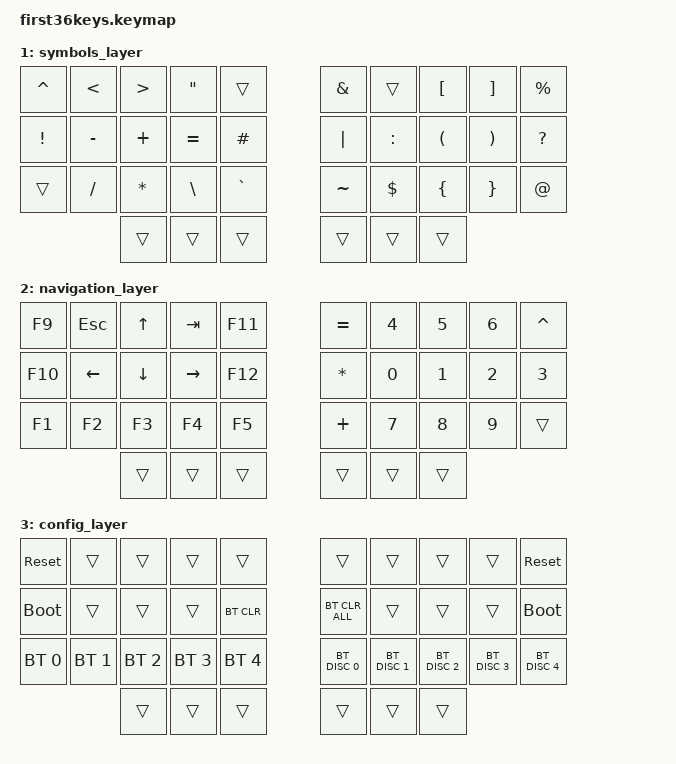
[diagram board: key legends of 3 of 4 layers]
#include <behaviors.dtsi>
#include <dt-bindings/zmk/keys.h>
#include <dt-bindings/zmk/bt.h>

// Home row mods macro
#define HRML(k1,k2,k3,k4) &ht_LEFT_PINKY LGUI k1  &ht_LEFT_RING LALT k2  &ht_LEFT_MIDDLE LCTRL k3  &ht_LEFT_INDEX LSHFT k4
#define HRMR(k1,k2,k3,k4) &ht_RIGHT_PINKY RSHFT k1  &ht_RIGHT_RING RCTRL k2  &ht_RIGHT_MIDDLE RALT k3  &ht_RIGHT_INDEX RGUI k4
#define LEFT_PINKY_HOLDING_TIME 250
#define LEFT_RING_HOLDING_TIME 200
#define LEFT_MIDDLE_HOLDING_TIME 200
#define LEFT_INDEX_HOLDING_TIME 200
#define RIGHT_PINKY_HOLDING_TIME 250
#define RIGHT_RING_HOLDING_TIME 200
#define RIGHT_MIDDLE_HOLDING_TIME 200
#define RIGHT_INDEX_HOLDING_TIME 200

/ {

    keymap {
        compatible = "zmk,keymap";
        default_layer {
            bindings = <
/*        ╭──────────┬──────────┬──────────┬──────────┬──────────╮   ╭──────────┬──────────┬──────────┬──────────┬──────────╮*/
/*        │  J       │  C       │  Y       │  F       │  K       │   │  Z       │  L       │  , <     │  U       │  Q       │*/
            &kp J      &kp C      &kp Y      &kp F      &kp K          &kp Z      &kp L      &kp COMMA  &kp U      &kp Q
/*        ├──────────┼──────────┼──────────┼──────────┼──────────┤   ├──────────┼──────────┼──────────┼──────────┼──────────┤*/
/*        │  R       │  S       │  T       │  H       │  D       │   │  M       │  N       │  A       │  I       │  O       │*/
            HRML(R,        S,         T,         H)     &kp D          &kp M      HRMR(N,        A,         I,        O)
/*        ├──────────┼──────────┼──────────┼──────────┼──────────┤   ├──────────┼──────────┼──────────┼──────────┼──────────┤*/
/*        │  '       │  V       │  G       │  P       │  B       │   │  X       │  W       │          │ ; :      │ . <      │*/
            &kp APOS   &kp V      &kp G      &kp P      &kp B          &kp X      &kp W      &kp ENTER  &kp SEMI   &kp DOT 
/*        ╰──────────┴──────────┴──────────┼──────────┼──────────┤   ├──────────┼──────────┼──────────┴──────────┴──────────╯*/
                                  &kp E      &sl 1      &sl 2          &sk RSHFT &shift_backspace   &kp SPACE
/*                              ╰──────────┴──────────┴──────────╯   ╰──────────┴──────────┴──────────╯*/
            >;
        };

        symbols_layer {
            bindings = <
/*        ╭──────────┬──────────┬──────────┬──────────┬──────────╮   ╭──────────┬──────────┬──────────┬──────────┬──────────╮*/
/*        │ ^        │  <       │  >       │  DQT     │          │   │  &       │          │  [       │  ]       │  %       │*/
            &kp CARET   &kp LT     &kp GT     &kp DQT    &trans         &kp AMPS   &trans     &kp LBKT   &kp RBKT   &kp PRCNT
/*        ├──────────┼──────────┼──────────┼──────────┼──────────┤   ├──────────┼──────────┼──────────┼──────────┼──────────┤*/
/*        │ !        │  -       │  +       │  =       │  #       │   │  |       │  :       │  (       │  )       │  ?       │*/
            &kp EXCL   &kp MINUS  &kp PLUS   &kp EQUAL  &kp HASH       &kp PIPE   &kp COLON  &kp LPAR   &kp RPAR   &kp QMARK
/*        ├──────────┼──────────┼──────────┼──────────┼──────────┤   ├──────────┼──────────┼──────────┼──────────┼──────────┤*/
/*        │          │  /       │  *       │  \       │  `       │   │  ~       │  $       │  {       │  }       │  @       │*/
            &trans     &kp FSLH   &kp STAR   &kp BSLH   &kp GRAVE      &kp TILDE  &kp DLLR   &kp LBRC   &kp RBRC   &kp AT
/*        ╰──────────┴──────────┴──────────┼──────────┼──────────┤   ├──────────┼──────────┼──────────┴──────────┴──────────╯*/
                                  &trans     &trans     &trans         &trans     &trans     &trans
/*                              ╰──────────┴──────────┴──────────╯   ╰──────────┴──────────┴──────────╯*/
            >;
        };

        navigation_layer {
            bindings = <
/*        ╭──────────┬──────────┬──────────┬──────────┬──────────╮   ╭──────────┬──────────┬──────────┬──────────┬──────────╮*/
/*        │          │  ESC     │  UP      │  TAB     │          │   │  =       │  4       │  5       │  6       │  ^       │*/
            &kp F9     &kp ESC    &kp UP     &kp TAB    &kp F11        &kp EQUAL  &kp N4     &kp N5     &kp N6     &kp CARET
/*        ├──────────┼──────────┼──────────┼──────────┼──────────┤   ├──────────┼──────────┼──────────┼──────────┼──────────┤*/
/*        │          │  LEFT    │  DOWN    │  RIGHT   │          │   │  *       │  0       │  1       │  2       │  3       │*/
            &kp F10     &kp LEFT   &kp DOWN   &kp RIGHT &kp F12         &kp STAR   &kp N0     &kp N1     &kp N2     &kp N3
/*        ├──────────┼──────────┼──────────┼──────────┼──────────┤   ├──────────┼──────────┼──────────┼──────────┼──────────┤*/
/*        │  F1      │  F2      │  F3      │  F4      │  F5      │   │  +       │  7       │  8       │  9       │  .       │*/
            &kp F1     &kp F2     &kp F3     &kp F4     &kp F5         &kp PLUS   &kp N7     &kp N8     &kp N9     &trans
/*        ╰──────────┴──────────┴──────────┼──────────┼──────────┤   ├──────────┼──────────┼──────────┴──────────┴──────────╯*/
                                  &trans     &trans     &trans         &trans     &trans     &trans
/*                              ╰──────────┴──────────┴──────────╯   ╰──────────┴──────────┴──────────╯*/
            >;
        };

        config_layer {
            bindings = <
/*        ╭──────────┬──────────┬──────────┬──────────┬──────────╮   ╭──────────┬──────────┬──────────┬──────────┬──────────╮*/
/*        │ RESET    │          │          │          │          │   │          │          │          │          │  RESET   │*/
           &sys_reset  &trans     &trans     &trans    &trans          &trans     &trans     &trans     &trans    &sys_reset
/*        ├──────────┼──────────┼──────────┼──────────┼──────────┤   ├──────────┼──────────┼──────────┼──────────┼──────────┤*/
/*        │BOOTLOADER│          │          │          │BT CLEAR  │   │          │          │          │          │BOOTLOADER│*/
          &bootloader  &trans     &trans     &trans    &bt BT_CLR     &bt BT_CLR_ALL &trans  &trans     &trans    &bootloader
/*        ├──────────┼──────────┼──────────┼──────────┼──────────┤   ├──────────┼──────────┼──────────┼──────────┼──────────┤*/
/*        │PROFILE 0 │PROFILE 1 │PROFILE 2 │PROFILE 3 │PROFILE 4 │   │          │          │          │          │          │*/
 &bt BT_SEL 0 &bt BT_SEL 1 &bt BT_SEL 2 &bt BT_SEL 3 &bt BT_SEL 4     &bt BT_DISC 0 &bt BT_DISC 1 &bt BT_DISC 2 &bt BT_DISC 3 &bt BT_DISC 4
/*        ╰──────────┴──────────┴──────────┼──────────┼──────────┤   ├──────────┼──────────┼──────────┴──────────┴──────────╯*/
                                  &trans     &trans     &trans         &trans     &trans     &trans
/*                              ╰──────────┴──────────┴──────────╯   ╰──────────┴──────────┴──────────╯*/
            >;
        };
    };
    conditional_layers {
        compatible = "zmk,conditional-layers";
        config_layer {
            if-layers = <1 2>;
            then-layer = <3>;
        };
    };
    
    behaviors {
        ht_LEFT_PINKY: hold_tap {
            compatible = "zmk,behavior-hold-tap";
            #binding-cells = <2>;
            flavor = "tap-preferred";
            tapping-term-ms = <LEFT_PINKY_HOLDING_TIME>;
            quick-tap-ms = <300>;
            require-prior-idle-ms = <250>;
            bindings = <&kp>, <&kp>;
        };
    };

    behaviors {
        ht_LEFT_RING: hold_tap {
            compatible = "zmk,behavior-hold-tap";
            #binding-cells = <2>;
            flavor = "tap-preferred";
            tapping-term-ms = <LEFT_RING_HOLDING_TIME>;
            quick-tap-ms = <300>;
            require-prior-idle-ms = <250>;
            bindings = <&kp>, <&kp>;
        };
    };
    
    behaviors {
        ht_LEFT_MIDDLE: hold_tap {
            compatible = "zmk,behavior-hold-tap";
            #binding-cells = <2>;
            flavor = "tap-preferred";
            tapping-term-ms = <LEFT_MIDDLE_HOLDING_TIME>;
            quick-tap-ms = <300>;
            require-prior-idle-ms = <250>;
            bindings = <&kp>, <&kp>;
        };
    };

    behaviors {
        ht_LEFT_INDEX: hold_tap {
            compatible = "zmk,behavior-hold-tap";
            #binding-cells = <2>;
            flavor = "tap-preferred";
            tapping-term-ms = <LEFT_INDEX_HOLDING_TIME>;
            quick-tap-ms = <300>;
            require-prior-idle-ms = <150>;
            bindings = <&kp>, <&kp>;
        };
    };
    
    behaviors {
        ht_RIGHT_PINKY: hold_tap {
            compatible = "zmk,behavior-hold-tap";
            #binding-cells = <2>;
            flavor = "tap-preferred";
            tapping-term-ms = <RIGHT_PINKY_HOLDING_TIME>;
            quick-tap-ms = <300>;
            require-prior-idle-ms = <250>;
            bindings = <&kp>, <&kp>;
        };
    };

    behaviors {
        ht_RIGHT_RING: hold_tap {
            compatible = "zmk,behavior-hold-tap";
            #binding-cells = <2>;
            flavor = "tap-preferred";
            tapping-term-ms = <RIGHT_RING_HOLDING_TIME>;
            quick-tap-ms = <300>;
            require-prior-idle-ms = <250>;
            bindings = <&kp>, <&kp>;
        };
    };
    
    behaviors {
        ht_RIGHT_MIDDLE: hold_tap {
            compatible = "zmk,behavior-hold-tap";
            #binding-cells = <2>;
            flavor = "tap-preferred";
            tapping-term-ms = <RIGHT_MIDDLE_HOLDING_TIME>;
            quick-tap-ms = <300>;
            require-prior-idle-ms = <250>;
            bindings = <&kp>, <&kp>;
        };
    };

    behaviors {
        ht_RIGHT_INDEX: hold_tap {
            compatible = "zmk,behavior-hold-tap";
            #binding-cells = <2>;
            flavor = "tap-preferred";
            tapping-term-ms = <RIGHT_INDEX_HOLDING_TIME>;
            quick-tap-ms = <300>;
            require-prior-idle-ms = <150>;
            bindings = <&kp>, <&kp>;
        };
    };

    behaviors {
        shift_backspace: shift_backspace {
            compatible = "zmk,behavior-mod-morph";
            #binding-cells = <0>;
            bindings = <&kp BACKSPACE>, <&kp DELETE>;
            mods = <(MOD_LSFT|MOD_RSFT)>;
        };
    };
};
